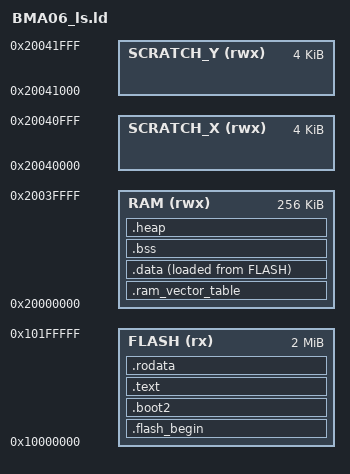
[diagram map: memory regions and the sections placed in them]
/* Life with David BMA06 - linker script
   Bootloader 2 goes to FLASH at 0x10000000, vector table at 0x10000100, "reset" at 0x10000200
*/

MEMORY
{
    FLASH(rx) : ORIGIN = 0x10000000, LENGTH = 2048k
    RAM(rwx) : ORIGIN =  0x20000000, LENGTH = 256k
    SCRATCH_X(rwx) : ORIGIN = 0x20040000, LENGTH = 4k
    SCRATCH_Y(rwx) : ORIGIN = 0x20041000, LENGTH = 4k
}

 ENTRY(_entry_point)


SECTIONS
{
 /* Second stage bootloader is prepended to the image. It must be 256 bytes big
       and checksummed. It is usually built by the boot_stage2 target
       in the Raspberry Pi Pico SDK
    */

    .flash_begin : {
        __flash_binary_start = .;
    } > FLASH

    .boot2 : {
        __boot2_start__ = .;
        KEEP (*(.boot2))
        __boot2_end__ = .;
    } > FLASH

    ASSERT(__boot2_end__ - __boot2_start__ == 256,
        "ERROR: Pico second stage bootloader must be 256 bytes in size")

    /* The second stage will always enter the image at the start of .text.
       The debugger will use the ELF entry point, which is the _entry_point
       symbol if present, otherwise defaults to start of .text.
       This can be used to transfer control back to the bootrom on debugger
       launches only, to perform proper flash setup.
    */

    .text : {
        __logical_binary_start = .;
        KEEP (*(.vectors))
        KEEP (*(.binary_info_header))
        __binary_info_header_end = .;
		. = __logical_binary_start + 0x100;
        KEEP (*(.reset))
		} > FLASH	
		
	.rodata : {
        . = ALIGN(4);
        *(.rodata*)
        . = ALIGN(4);
        *(SORT_BY_ALIGNMENT(SORT_BY_NAME(.flashdata*)))
        . = ALIGN(4);
    } > FLASH
	
	.ram_vector_table (COPY): {
        *(.ram_vector_table)
    } > RAM

    .data : {
        __data_start__ = .;
		
		 *(.data*)
		 . = ALIGN(4);
        __data_end__ = .;
    } > RAM AT> FLASH
	
	
    .bss  : {
        . = ALIGN(4);
        __bss_start__ = .;
        *(SORT_BY_ALIGNMENT(SORT_BY_NAME(.bss*)))
        *(COMMON)
        . = ALIGN(4);
        __bss_end__ = .;
    } > RAM
	
    .heap (COPY):
    {
        __end__ = .;
        end = __end__;
        *(.heap*)
        __HeapLimit = .;
    } > RAM
}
